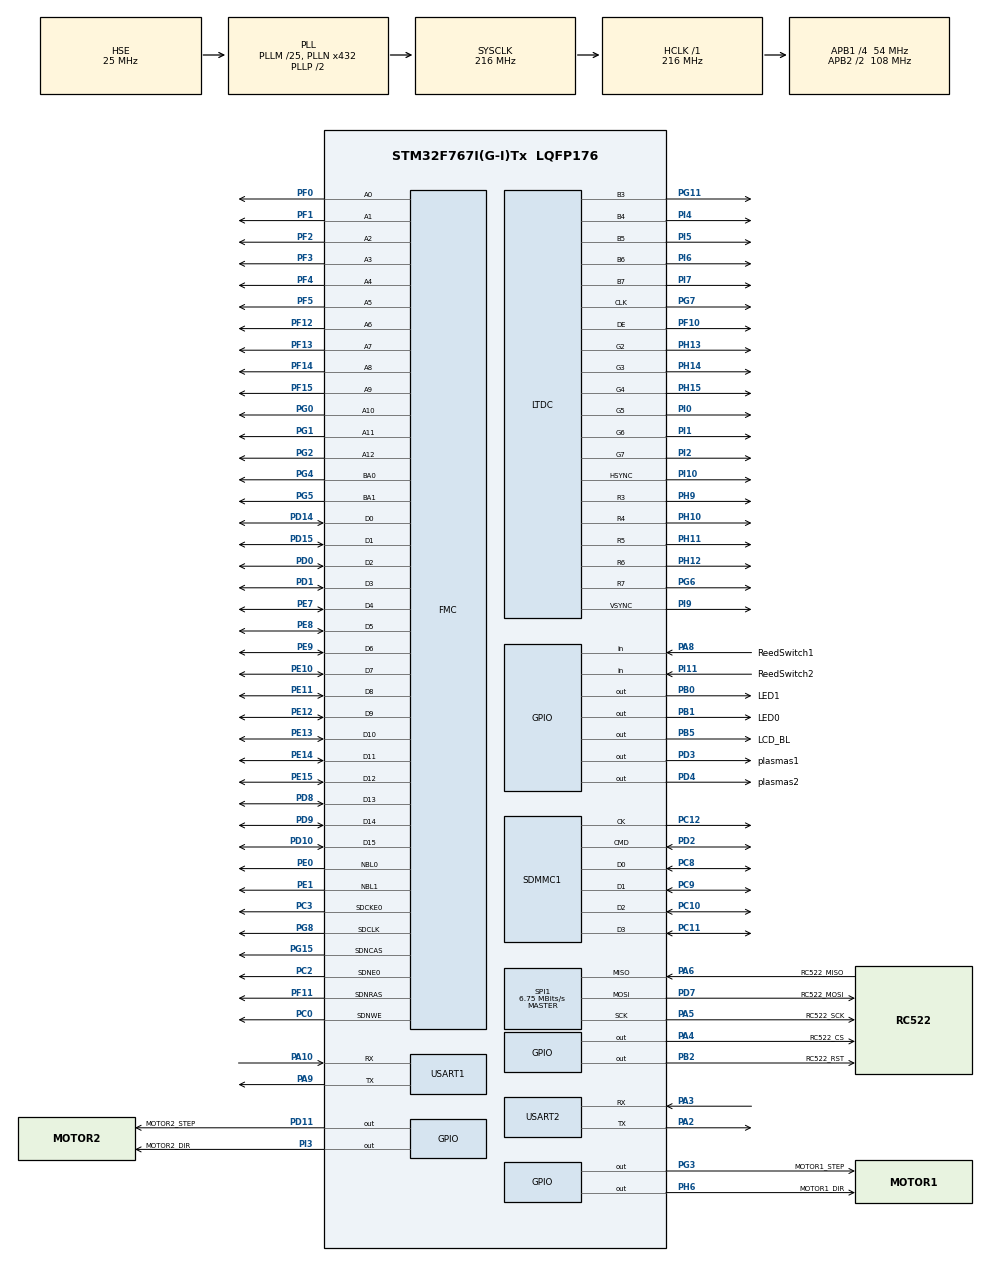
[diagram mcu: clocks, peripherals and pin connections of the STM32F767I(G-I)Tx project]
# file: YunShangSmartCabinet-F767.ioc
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CORTEX_M7.Enable_Spec=__NULL
CORTEX_M7.MPU_Control=__NULL
CORTEX_M7.default_mode_Activation=1
DMA2D.ColorMode=DMA2D_OUTPUT_RGB565
Dma.Request0=USART2_RX
Dma.Request1=USART2_TX
Dma.Request2=SDMMC1_RX
Dma.Request3=SDMMC1_TX
Dma.SDMMC1_RX.2.Direction=DMA_PERIPH_TO_MEMORY
Dma.SDMMC1_RX.2.FIFOMode=DMA_FIFOMODE_ENABLE
Dma.SDMMC1_RX.2.FIFOThreshold=DMA_FIFO_THRESHOLD_FULL
Dma.SDMMC1_RX.2.Instance=DMA2_Stream3
Dma.SDMMC1_RX.2.MemBurst=DMA_MBURST_INC4
Dma.SDMMC1_RX.2.MemDataAlignment=DMA_MDATAALIGN_WORD
Dma.SDMMC1_RX.2.MemInc=DMA_MINC_ENABLE
Dma.SDMMC1_RX.2.Mode=DMA_PFCTRL
Dma.SDMMC1_RX.2.PeriphBurst=DMA_PBURST_INC4
Dma.SDMMC1_RX.2.PeriphDataAlignment=DMA_PDATAALIGN_WORD
Dma.SDMMC1_RX.2.PeriphInc=DMA_PINC_DISABLE
Dma.SDMMC1_RX.2.Priority=DMA_PRIORITY_LOW
Dma.SDMMC1_TX.3.Direction=DMA_MEMORY_TO_PERIPH
Dma.SDMMC1_TX.3.FIFOMode=DMA_FIFOMODE_ENABLE
Dma.SDMMC1_TX.3.FIFOThreshold=DMA_FIFO_THRESHOLD_FULL
Dma.SDMMC1_TX.3.Instance=DMA2_Stream6
Dma.SDMMC1_TX.3.MemBurst=DMA_MBURST_INC4
Dma.SDMMC1_TX.3.MemDataAlignment=DMA_MDATAALIGN_WORD
Dma.SDMMC1_TX.3.MemInc=DMA_MINC_ENABLE
Dma.SDMMC1_TX.3.Mode=DMA_PFCTRL
Dma.SDMMC1_TX.3.PeriphBurst=DMA_PBURST_INC4
Dma.SDMMC1_TX.3.PeriphDataAlignment=DMA_PDATAALIGN_WORD
Dma.SDMMC1_TX.3.PeriphInc=DMA_PINC_DISABLE
Dma.SDMMC1_TX.3.Priority=DMA_PRIORITY_LOW
Dma.USART2_RX.0.Direction=DMA_PERIPH_TO_MEMORY
Dma.USART2_RX.0.FIFOMode=DMA_FIFOMODE_DISABLE
Dma.USART2_RX.0.Instance=DMA1_Stream5
Dma.USART2_RX.0.MemDataAlignment=DMA_MDATAALIGN_BYTE
Dma.USART2_RX.0.MemInc=DMA_MINC_ENABLE
Dma.USART2_RX.0.Mode=DMA_NORMAL
Dma.USART2_RX.0.PeriphDataAlignment=DMA_PDATAALIGN_BYTE
Dma.USART2_RX.0.PeriphInc=DMA_PINC_DISABLE
Dma.USART2_RX.0.Priority=DMA_PRIORITY_LOW
Dma.USART2_TX.1.Direction=DMA_MEMORY_TO_PERIPH
Dma.USART2_TX.1.FIFOMode=DMA_FIFOMODE_DISABLE
Dma.USART2_TX.1.Instance=DMA1_Stream6
Dma.USART2_TX.1.MemDataAlignment=DMA_MDATAALIGN_BYTE
Dma.USART2_TX.1.MemInc=DMA_MINC_ENABLE
Dma.USART2_TX.1.Mode=DMA_NORMAL
Dma.USART2_TX.1.PeriphDataAlignment=DMA_PDATAALIGN_BYTE
Dma.USART2_TX.1.PeriphInc=DMA_PINC_DISABLE
Dma.USART2_TX.1.Priority=DMA_PRIORITY_LOW
FATFS._CODE_PAGE=936
FATFS._FS_EXFAT=1
FATFS._MAX_SS=4096
FATFS._USE_LFN=2
FMC.CASLatency1=FMC_SDRAM_CAS_LATENCY_3
FMC.ColumnBitsNumber1=FMC_SDRAM_COLUMN_BITS_NUM_9
FMC.ExitSelfRefreshDelay1=8
FMC.LoadToActiveDelay1=2
FMC.RCDDelay1=2
FMC.RPDelay1=2
FMC.RPDelay2=2
FMC.ReadBurst1=FMC_SDRAM_RBURST_ENABLE
FMC.ReadBurst2=FMC_SDRAM_RBURST_ENABLE
FMC.ReadPipeDelay1=FMC_SDRAM_RPIPE_DELAY_1
FMC.ReadPipeDelay2=FMC_SDRAM_RPIPE_DELAY_1
FMC.RowCycleDelay1=6
FMC.RowCycleDelay2=6
FMC.SDClockPeriod1=FMC_SDRAM_CLOCK_PERIOD_2
FMC.SDClockPeriod2=FMC_SDRAM_CLOCK_PERIOD_2
FMC.SelfRefreshTime1=6
FMC.WriteRecoveryTime1=4
FREERTOS.Tasks01=defaultTask,24,128,StartDefaultTask,Default,NULL,Dynamic,NULL,NULL
FREERTOS.configCHECK_FOR_STACK_OVERFLOW=1
FREERTOS.configTOTAL_HEAP_SIZE=65536 
LTDC.ActiveW=800
LTDC.Alpha_L0=255
LTDC.FBStartAdress_L0=0xc0000000
LTDC.HBP=88
LTDC.HFP=40
LTDC.HSync=48
LTDC.ImageHeight_L0=480
LTDC.ImageWidth_L0=800
LTDC.Layers=0
LTDC.PixelFormat_L0=LTDC_PIXEL_FORMAT_RGB565
LTDC.VBP=32
LTDC.VFP=13
LTDC.VSync=3
LTDC.WindowX1_L0=800
LTDC.WindowY1_L0=480
Mcu.Family=STM32F7
Mcu.Name=STM32F767I(G-I)Tx
Mcu.Package=LQFP176
NVIC.DMA1_Stream5_IRQn=true\:5\:0\:false\:false\:true\:true\:false\:true\:true
NVIC.DMA1_Stream6_IRQn=true\:5\:0\:false\:false\:true\:true\:false\:true\:true
NVIC.DMA2D_IRQn=true\:5\:0\:false\:false\:true\:true\:true\:true\:true
NVIC.DMA2_Stream3_IRQn=true\:5\:0\:false\:false\:true\:true\:false\:true\:true
NVIC.DMA2_Stream6_IRQn=true\:5\:0\:false\:false\:true\:true\:false\:true\:true
NVIC.LTDC_IRQn=true\:5\:0\:false\:false\:true\:true\:true\:true\:true
NVIC.PriorityGroup=NVIC_PRIORITYGROUP_4
NVIC.RTC_Alarm_IRQn=true\:5\:0\:false\:false\:true\:true\:true\:true\:true
NVIC.SDMMC1_IRQn=true\:5\:0\:false\:false\:true\:true\:true\:true\:true
NVIC.TIM1_UP_TIM10_IRQn=true\:15\:0\:false\:false\:true\:false\:false\:true\:true
NVIC.TIM6_DAC_IRQn=true\:5\:0\:false\:false\:true\:true\:true\:true\:true
NVIC.TIM7_IRQn=true\:5\:0\:false\:false\:true\:true\:true\:true\:true
NVIC.TimeBase=TIM1_UP_TIM10_IRQn
NVIC.TimeBaseIP=TIM1
NVIC.USART2_IRQn=true\:5\:0\:false\:false\:true\:true\:true\:true\:true
PA10.Mode=Asynchronous
PA10.Signal=USART1_RX
PA13.Mode=Serial_Wire
PA13.Signal=SYS_JTMS-SWDIO
PA14.Mode=Serial_Wire
PA14.Signal=SYS_JTCK-SWCLK
PA2.Mode=Asynchronous
PA2.Signal=USART2_TX
PA3.Mode=Asynchronous
PA3.Signal=USART2_RX
PA4.GPIO_Label=RC522_CS
PA4.Signal=GPIO_Output
PA5.GPIO_Label=RC522_SCK
PA5.Mode=Full_Duplex_Master
PA5.Signal=SPI1_SCK
PA6.GPIO_Label=RC522_MISO
PA6.Mode=Full_Duplex_Master
PA6.Signal=SPI1_MISO
PA8.GPIO_Label=ReedSwitch1
PA8.Signal=GPIO_Input
PA9.Mode=Asynchronous
PA9.Signal=USART1_TX
PB0.GPIO_Label=LED1
PB0.PinState=GPIO_PIN_SET
PB0.Signal=GPIO_Output
PB1.GPIO_Label=LED0
PB1.PinState=GPIO_PIN_SET
PB1.Signal=GPIO_Output
PB2.GPIO_Label=RC522_RST
PB2.Signal=GPIO_Output
PB5.GPIO_Label=LCD_BL
PB5.Signal=GPIO_Output
PC0.Signal=FMC_SDNWE
PC10.GPIO_PuPd=GPIO_PULLUP
PC10.Mode=SD_4_bits_Wide_bus
PC10.Signal=SDMMC1_D2
PC11.GPIO_PuPd=GPIO_PULLUP
PC11.Mode=SD_4_bits_Wide_bus
PC11.Signal=SDMMC1_D3
PC12.GPIO_PuPd=GPIO_PULLUP
PC12.Mode=SD_4_bits_Wide_bus
PC12.Signal=SDMMC1_CK
PC14/OSC32_IN.Mode=LSE-External-Oscillator
PC14/OSC32_IN.Signal=RCC_OSC32_IN
PC15/OSC32_OUT.Mode=LSE-External-Oscillator
PC15/OSC32_OUT.Signal=RCC_OSC32_OUT
PC2.Mode=SdramChipSelect1_1
PC2.Signal=FMC_SDNE0
PC3.Mode=SdramChipSelect1_1
PC3.Signal=FMC_SDCKE0
PC8.GPIO_PuPd=GPIO_PULLUP
PC8.Mode=SD_4_bits_Wide_bus
PC8.Signal=SDMMC1_D0
PC9.GPIO_PuPd=GPIO_PULLUP
PC9.Mode=SD_4_bits_Wide_bus
PC9.Signal=SDMMC1_D1
PD0.Signal=FMC_D2_DA2
PD1.Signal=FMC_D3_DA3
PD10.Signal=FMC_D15_DA15
PD11.GPIO_Label=MOTOR2_STEP
PD11.Signal=GPIO_Output
PD14.Signal=FMC_D0_DA0
PD15.Signal=FMC_D1_DA1
PD2.GPIO_PuPd=GPIO_PULLUP
PD2.Mode=SD_4_bits_Wide_bus
PD2.Signal=SDMMC1_CMD
PD3.GPIO_Label=plasmas1
PD3.GPIO_ModeDefaultOutputPP=GPIO_MODE_OUTPUT_OD
PD3.GPIO_PuPd=GPIO_NOPULL
PD3.Signal=GPIO_Output
PD4.GPIO_Label=plasmas2
PD4.Signal=GPIO_Output
PD7.GPIO_Label=RC522_MOSI
PD7.Mode=Full_Duplex_Master
PD7.Signal=SPI1_MOSI
PD8.Signal=FMC_D13_DA13
PD9.Signal=FMC_D14_DA14
PE0.Signal=FMC_NBL0
PE1.Signal=FMC_NBL1
PE10.Signal=FMC_D7_DA7
PE11.Signal=FMC_D8_DA8
PE12.Signal=FMC_D9_DA9
PE13.Signal=FMC_D10_DA10
PE14.Signal=FMC_D11_DA11
PE15.Signal=FMC_D12_DA12
PE7.Signal=FMC_D4_DA4
PE8.Signal=FMC_D5_DA5
PE9.Signal=FMC_D6_DA6
PF0.Signal=FMC_A0
PF1.Signal=FMC_A1
PF10.GPIO_Speed=GPIO_SPEED_FREQ_HIGH
PF10.Mode=RGB565
PF10.Signal=LTDC_DE
PF11.Signal=FMC_SDNRAS
PF12.Signal=FMC_A6
PF13.Signal=FMC_A7
PF14.Signal=FMC_A8
PF15.Signal=FMC_A9
PF2.Signal=FMC_A2
PF3.Signal=FMC_A3
PF4.Signal=FMC_A4
PF5.Signal=FMC_A5
PG0.Signal=FMC_A10
PG1.Signal=FMC_A11
PG11.GPIO_Speed=GPIO_SPEED_FREQ_HIGH
PG11.Mode=RGB565
PG11.Signal=LTDC_B3
PG15.Signal=FMC_SDNCAS
PG2.Signal=FMC_A12
PG3.GPIO_Label=MOTOR1_STEP
PG3.Signal=GPIO_Output
PG4.Signal=FMC_A14_BA0
PG5.Signal=FMC_A15_BA1
PG6.GPIO_Speed=GPIO_SPEED_FREQ_HIGH
PG6.Mode=RGB565
PG6.Signal=LTDC_R7
PG7.GPIO_Speed=GPIO_SPEED_FREQ_HIGH
PG7.Mode=RGB565
PG7.Signal=LTDC_CLK
PG8.Signal=FMC_SDCLK
PH0/OSC_IN.Mode=HSE-External-Oscillator
PH0/OSC_IN.Signal=RCC_OSC_IN
PH1/OSC_OUT.Mode=HSE-External-Oscillator
PH1/OSC_OUT.Signal=RCC_OSC_OUT
PH10.GPIO_Speed=GPIO_SPEED_FREQ_HIGH
PH10.Mode=RGB565
PH10.Signal=LTDC_R4
PH11.GPIO_Speed=GPIO_SPEED_FREQ_HIGH
PH11.Mode=RGB565
PH11.Signal=LTDC_R5
PH12.GPIO_Speed=GPIO_SPEED_FREQ_HIGH
PH12.Mode=RGB565
PH12.Signal=LTDC_R6
PH13.GPIO_Speed=GPIO_SPEED_FREQ_HIGH
PH13.Mode=RGB565
PH13.Signal=LTDC_G2
PH14.GPIO_Speed=GPIO_SPEED_FREQ_HIGH
PH14.Mode=RGB565
PH14.Signal=LTDC_G3
PH15.GPIO_Speed=GPIO_SPEED_FREQ_HIGH
PH15.Mode=RGB565
PH15.Signal=LTDC_G4
PH6.GPIO_Label=MOTOR1_DIR
PH6.Signal=GPIO_Output
PH9.GPIO_Speed=GPIO_SPEED_FREQ_HIGH
PH9.Mode=RGB565
PH9.Signal=LTDC_R3
PI0.GPIO_Speed=GPIO_SPEED_FREQ_HIGH
PI0.Mode=RGB565
PI0.Signal=LTDC_G5
PI1.GPIO_Speed=GPIO_SPEED_FREQ_HIGH
PI1.Mode=RGB565
PI1.Signal=LTDC_G6
PI10.GPIO_Speed=GPIO_SPEED_FREQ_HIGH
PI10.Mode=RGB565
PI10.Signal=LTDC_HSYNC
PI11.GPIO_Label=ReedSwitch2
PI11.Signal=GPIO_Input
PI2.GPIO_Speed=GPIO_SPEED_FREQ_HIGH
PI2.Mode=RGB565
PI2.Signal=LTDC_G7
PI3.GPIO_Label=MOTOR2_DIR
PI3.Signal=GPIO_Output
PI4.GPIO_Speed=GPIO_SPEED_FREQ_HIGH
PI4.Mode=RGB565
PI4.Signal=LTDC_B4
PI5.GPIO_Speed=GPIO_SPEED_FREQ_HIGH
PI5.Mode=RGB565
PI5.Signal=LTDC_B5
PI6.GPIO_Speed=GPIO_SPEED_FREQ_HIGH
PI6.Mode=RGB565
PI6.Signal=LTDC_B6
PI7.GPIO_Speed=GPIO_SPEED_FREQ_HIGH
PI7.Mode=RGB565
PI7.Signal=LTDC_B7
PI9.GPIO_Speed=GPIO_SPEED_FREQ_HIGH
PI9.Mode=RGB565
PI9.Signal=LTDC_VSYNC
ProjectManager.HeapSize=0x200
ProjectManager.StackSize=0x1000
ProjectManager.TargetToolchain=Makefile
RCC.AHBFreq_Value=216000000
RCC.APB1CLKDivider=RCC_HCLK_DIV4
RCC.APB1Freq_Value=54000000
RCC.APB1TimFreq_Value=108000000
RCC.APB2CLKDivider=RCC_HCLK_DIV2
RCC.APB2Freq_Value=108000000
RCC.APB2TimFreq_Value=216000000
RCC.CortexFreq_Value=216000000
RCC.HCLKFreq_Value=216000000
RCC.HSE_VALUE=25000000
RCC.HSI_VALUE=16000000
RCC.PLLM=25
RCC.PLLN=432
RCC.PLLQ=9
RCC.PLLSourceVirtual=RCC_PLLSOURCE_HSE
RCC.RTCClockSelection=RCC_RTCCLKSOURCE_LSE
RCC.SDMMCClockSelection=RCC_SDMMC1CLKSOURCE_CLK48
RCC.SYSCLKFreq_VALUE=216000000
RCC.SYSCLKSource=RCC_SYSCLKSOURCE_PLLCLK
RCC.USBFreq_Value=48000000
RCC.VCOOutputFreq_Value=432000000
RTC.Alarm-Alarm\ A=RTC_ALARM_A
RTC.Format=RTC_FORMAT_BIN
SDMMC1.ClockDiv=5
SH.FMC_A0.0=FMC_A0,13b-sda1
SH.FMC_A1.0=FMC_A1,13b-sda1
SH.FMC_A10.0=FMC_A10,13b-sda1
SH.FMC_A11.0=FMC_A11,13b-sda1
SH.FMC_A12.0=FMC_A12,13b-sda1
SH.FMC_A14_BA0.0=FMC_BA0,FourSdramBanks1
SH.FMC_A15_BA1.0=FMC_BA1,FourSdramBanks1
SH.FMC_A2.0=FMC_A2,13b-sda1
SH.FMC_A3.0=FMC_A3,13b-sda1
SH.FMC_A4.0=FMC_A4,13b-sda1
SH.FMC_A5.0=FMC_A5,13b-sda1
SH.FMC_A6.0=FMC_A6,13b-sda1
SH.FMC_A7.0=FMC_A7,13b-sda1
SH.FMC_A8.0=FMC_A8,13b-sda1
SH.FMC_A9.0=FMC_A9,13b-sda1
SH.FMC_D0_DA0.0=FMC_D0,sd-16b-d1
SH.FMC_D10_DA10.0=FMC_D10,sd-16b-d1
SH.FMC_D11_DA11.0=FMC_D11,sd-16b-d1
SH.FMC_D12_DA12.0=FMC_D12,sd-16b-d1
SH.FMC_D13_DA13.0=FMC_D13,sd-16b-d1
SH.FMC_D14_DA14.0=FMC_D14,sd-16b-d1
SH.FMC_D15_DA15.0=FMC_D15,sd-16b-d1
SH.FMC_D1_DA1.0=FMC_D1,sd-16b-d1
SH.FMC_D2_DA2.0=FMC_D2,sd-16b-d1
SH.FMC_D3_DA3.0=FMC_D3,sd-16b-d1
SH.FMC_D4_DA4.0=FMC_D4,sd-16b-d1
SH.FMC_D5_DA5.0=FMC_D5,sd-16b-d1
SH.FMC_D6_DA6.0=FMC_D6,sd-16b-d1
SH.FMC_D7_DA7.0=FMC_D7,sd-16b-d1
SH.FMC_D8_DA8.0=FMC_D8,sd-16b-d1
SH.FMC_D9_DA9.0=FMC_D9,sd-16b-d1
SH.FMC_NBL0.0=FMC_NBL0,Sd2ByteEnable1
SH.FMC_NBL1.0=FMC_NBL1,Sd2ByteEnable1
SH.FMC_SDCLK.0=FMC_SDCLK,13b-sda1
SH.FMC_SDNCAS.0=FMC_SDNCAS,13b-sda1
SH.FMC_SDNRAS.0=FMC_SDNRAS,13b-sda1
SH.FMC_SDNWE.0=FMC_SDNWE,13b-sda1
SPI1.BaudRatePrescaler=SPI_BAUDRATEPRESCALER_16
SPI1.CalculateBaudRate=6.75 MBits/s
SPI1.DataSize=SPI_DATASIZE_8BIT
SPI1.Direction=SPI_DIRECTION_2LINES
SPI1.Mode=SPI_MODE_MASTER
SPI1.VirtualType=VM_MASTER
TIM6.Prescaler=108-1
TIM7.Prescaler=108-1
USART1.VirtualMode-Asynchronous=VM_ASYNC
USART2.VirtualMode-Asynchronous=VM_ASYNC
VP_DMA2D_VS_DMA2D.Mode=DMA2D_Activate
VP_FATFS_VS_SDIO.Mode=SDIO
VP_FREERTOS_VS_CMSIS_V2.Mode=CMSIS_V2
VP_RTC_VS_RTC_Activate.Mode=RTC_Enabled
VP_RTC_VS_RTC_Alarm_A_Intern.Mode=Alarm A
VP_RTC_VS_RTC_Calendar.Mode=RTC_Calendar
VP_SYS_VS_tim1.Mode=TIM1
VP_TIM6_VS_ClockSourceINT.Mode=Enable_Timer
VP_TIM7_VS_ClockSourceINT.Mode=Enable_Timer
board=custom

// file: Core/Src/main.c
/* USER CODE BEGIN Header */
/**
  ******************************************************************************
  * @file           : main.c
  * @brief          : Main program body
  ******************************************************************************
  * @attention
  *
  * Copyright (c) 2025 STMicroelectronics.
  * All rights reserved.
  *
  * This software is licensed under terms that can be found in the LICENSE file
  * in the root directory of this software component.
  * If no LICENSE file comes with this software, it is provided AS-IS.
  *
  ******************************************************************************
  */
/* USER CODE END Header */
#include "main.h"
#include "cmsis_os.h"
#include "dma.h"
#include "dma2d.h"
#include "fatfs.h"
#include "ltdc.h"
#include "rtc.h"
#include "sdmmc.h"
#include "spi.h"
#include "tim.h"
#include "usart.h"
#include "gpio.h"
#include "fmc.h"

/* USER CODE BEGIN Includes */
#include "motor_control_tasks.h"
#include "stepper_motor.h"
/* USER CODE END Includes */

void SystemClock_Config(void);
void MX_FREERTOS_Init(void);

int main(void)
{

  /* MCU Configuration--------------------------------------------------------*/

  /* Reset of all peripherals, Initializes the Flash interface and the Systick. */
  HAL_Init();

  /* Configure the system clock */
  SystemClock_Config();

  /* Initialize all configured peripherals */
  MX_GPIO_Init();
  MX_DMA_Init();
  MX_USART1_UART_Init();
  MX_FMC_Init();
  MX_DMA2D_Init();
  MX_LTDC_Init();
  MX_USART2_UART_Init();
  MX_TIM6_Init();
  MX_TIM7_Init();
  MX_SDMMC1_SD_Init();
  MX_FATFS_Init();
  MX_RTC_Init();
  MX_SPI1_Init();

  /* Init scheduler */
  osKernelInitialize();

  /* Call init function for freertos objects (in cmsis_os2.c) */
  MX_FREERTOS_Init();

  /* Start scheduler */
  osKernelStart();

  /* We should never get here as control is now taken by the scheduler */

  /* Infinite loop */
  while (1)
  {

  }
}

void SystemClock_Config(void)
{
  RCC_OscInitTypeDef RCC_OscInitStruct = {0};
  RCC_ClkInitTypeDef RCC_ClkInitStruct = {0};

  /** Configure LSE Drive Capability
  */
  HAL_PWR_EnableBkUpAccess();
  __HAL_RCC_LSEDRIVE_CONFIG(RCC_LSEDRIVE_LOW);

  /** Configure the main internal regulator output voltage
  */
  __HAL_RCC_PWR_CLK_ENABLE();
  __HAL_PWR_VOLTAGESCALING_CONFIG(PWR_REGULATOR_VOLTAGE_SCALE1);

  /** Initializes the RCC Oscillators according to the specified parameters
  * in the RCC_OscInitTypeDef structure.
  */
  RCC_OscInitStruct.OscillatorType = RCC_OSCILLATORTYPE_HSE|RCC_OSCILLATORTYPE_LSE;
  RCC_OscInitStruct.HSEState = RCC_HSE_ON;
  RCC_OscInitStruct.LSEState = RCC_LSE_ON;
  RCC_OscInitStruct.PLL.PLLState = RCC_PLL_ON;
  RCC_OscInitStruct.PLL.PLLSource = RCC_PLLSOURCE_HSE;
  RCC_OscInitStruct.PLL.PLLM = 25;
  RCC_OscInitStruct.PLL.PLLN = 432;
  RCC_OscInitStruct.PLL.PLLP = RCC_PLLP_DIV2;
  RCC_OscInitStruct.PLL.PLLQ = 9;
  RCC_OscInitStruct.PLL.PLLR = 2;
  if (HAL_RCC_OscConfig(&RCC_OscInitStruct) != HAL_OK)
  {
    Error_Handler();
  }

  /** Activate the Over-Drive mode
  */
  if (HAL_PWREx_EnableOverDrive() != HAL_OK)
  {
    Error_Handler();
  }

  /** Initializes the CPU, AHB and APB buses clocks
  */
  RCC_ClkInitStruct.ClockType = RCC_CLOCKTYPE_HCLK|RCC_CLOCKTYPE_SYSCLK
                              |RCC_CLOCKTYPE_PCLK1|RCC_CLOCKTYPE_PCLK2;
  RCC_ClkInitStruct.SYSCLKSource = RCC_SYSCLKSOURCE_PLLCLK;
  RCC_ClkInitStruct.AHBCLKDivider = RCC_SYSCLK_DIV1;
  RCC_ClkInitStruct.APB1CLKDivider = RCC_HCLK_DIV4;
  RCC_ClkInitStruct.APB2CLKDivider = RCC_HCLK_DIV2;

  if (HAL_RCC_ClockConfig(&RCC_ClkInitStruct, FLASH_LATENCY_7) != HAL_OK)
  {
    Error_Handler();
  }
}

void HAL_TIM_PeriodElapsedCallback(TIM_HandleTypeDef *htim)
{
  if (htim->Instance == TIM1)
  {
    HAL_IncTick();
  }
  /* USER CODE BEGIN Callback 1 */
  if(htim->Instance == TIM6)
  {
    stepper_motor_on_timer_interrupt(&motors[0]);
  }
  else if(htim->Instance == TIM7)
  {
    stepper_motor_on_timer_interrupt(&motors[1]);
  }
  /* USER CODE END Callback 1 */
}

void Error_Handler(void)
{
  __disable_irq();
  while (1)
  {
  }
}

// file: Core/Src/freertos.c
/* USER CODE BEGIN Header */
/**
 ******************************************************************************
 * File Name          : freertos.c
 * Description        : Code for freertos applications
 ******************************************************************************
 * @attention
 *
 * Copyright (c) 2025 STMicroelectronics.
 * All rights reserved.
 *
 * This software is licensed under terms that can be found in the LICENSE file
 * in the root directory of this software component.
 * If no LICENSE file comes with this software, it is provided AS-IS.
 *
 ******************************************************************************
 */
/* USER CODE END Header */

#include "FreeRTOS.h"
#include "task.h"
#include "main.h"
#include "cmsis_os.h"

/* USER CODE BEGIN Includes */
#include "led.h"
#include "tasks_init.h"
#include "modules_init.h"
#include "mqtt_message.h"
#include "fatfs.h"
#include "sdmmc.h"
#include "stdio.h"
#include "dwt.h"
/* USER CODE END Includes */

/* Definitions for defaultTask */
osThreadId_t defaultTaskHandle;
const osThreadAttr_t defaultTask_attributes = {
  .name = "defaultTask",
  .stack_size = 128 * 4,
  .priority = (osPriority_t) osPriorityNormal,
};

void StartDefaultTask(void *argument);

void MX_FREERTOS_Init(void); /* (MISRA C 2004 rule 8.1) */

/* Hook prototypes */
void vApplicationStackOverflowHook(xTaskHandle xTask, signed char *pcTaskName);

/* USER CODE BEGIN 4 */
void vApplicationStackOverflowHook(xTaskHandle xTask, signed char *pcTaskName)
{
    /* Run time stack overflow checking is performed if
    configCHECK_FOR_STACK_OVERFLOW is defined to 1 or 2. This hook function is
    called if a stack overflow is detected. */
}
/* USER CODE END 4 */

void MX_FREERTOS_Init(void) {
  /* USER CODE BEGIN Init */
    modeules_init();
    tasks_init();
  /* USER CODE END Init */

  /* Create the thread(s) */
  /* creation of defaultTask */
  defaultTaskHandle = osThreadNew(StartDefaultTask, NULL, &defaultTask_attributes);

}

void StartDefaultTask(void *argument)
{
  /* USER CODE BEGIN StartDefaultTask */

    /* Infinite loop */
    for (;;)
    {
        // mqtt_publish("control","nb");
        led_toggle(&LED0);
        osDelay(500);
    }
  /* USER CODE END StartDefaultTask */
}
